# psoc6_01 register map
Vendor: Cypress Semiconductor; Series: PSoC6_01; File version: 1.0
CPU: CM4 r0p1, little endian, MPU, FPU, VTOR, 3 interrupt priority bits
Registers are 32-bit, read-write, reset 0x0 unless marked. A register's access mark holds for its fields unless they carry their own. Offsets are from the block's base; [hi:lo] are bit positions; lines under a group give offsets from that group.

## BLE (part 1 of 5) — Bluetooth Low Energy Subsystem
Base 0x403C0000
0x00 RCB group — Radio Control Bus (RCB) controller
  0x00 CTRL reset 0xF80000 — RCB control register.
    [31] ENABLED, [23] DATA_WIDTH, [22:19] ADDR_WIDTH, [18:13] DIV, [12] DIV_ENABLED, [11:10] LAG, [9:8] LEAD, [5] SSEL_POLARITY, [4] SCLK_CONTINUOUS, [3] RX_CLK_SRC, [2] RX_CLK_EDGE, [1] TX_CLK_EDGE
  0x04 STATUS ro reset not defined — RCB status register.
    [0] BUS_BUSY — RCB bus is busy. The bus is considered busy ('1') during an ongoing transaction.
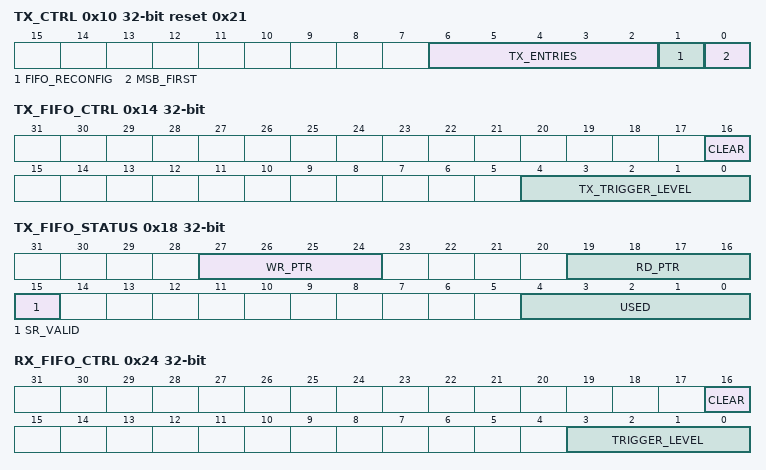
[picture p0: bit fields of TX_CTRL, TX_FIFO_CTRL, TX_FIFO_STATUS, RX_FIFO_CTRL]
  0x10 TX_CTRL reset 0x21 — Transmitter control register.
    [6:2] TX_ENTRIES — This field determines the depth of the TX_FIFO. Allowed legal values are 8 and 16 only
    [1] FIFO_RECONFIG — Setting this bit, clears the FIFO and resets the pointer
    [0] MSB_FIRST — Least significant bit first ('0') or most significant bit first ('1'). This field also affects the Address field When MSB_FIRST = 1, then [15:0] is data and [(ADDR_WIDTH+15):16] is used for address When MSB_FIRST = 0, then [15:0] is for data. No address field
  0x14 TX_FIFO_CTRL — Transmitter FIFO control register.
    [16] CLEAR — When '1', the transmitter FIFO and transmitter shift register are cleared/invalidated. Invalidation will last for as long as this field is '1'. If a quick clear/invalidation is required, the field should be set to '1' and be followed by a set to '0'. If a clear/invalidation is required for an extended time period, the field should be set to '1' during the complete time period.
    [4:0] TX_TRIGGER_LEVEL — Trigger level. When the transmitter FIFO has less entries than the number of this field, a transmitter trigger event is generated.
  0x18 TX_FIFO_STATUS ro — Transmitter FIFO status register.
    [27:24] WR_PTR — FIFO write pointer: FIFO location at which a new data frame is written.
    [19:16] RD_PTR — FIFO read pointer: FIFO location from which a data frame is read by the hardware.
    [15] SR_VALID — Indicates whether the TX shift registers holds a valid data frame ('1') or not ('0'). The shift register can be considered the top of the TX FIFO (the data frame is not included in the USED field of the TX FIFO). The shift register is a working register and holds the data frame that is currently transmitted (when the protocol state machine is transmitting a data frame) or the data frame that is tranmitted next (when the protocol state machine is not transmitting a data frame).
    [4:0] USED — Amount of enties in the transmitter FIFO. The value of this field ranges from 0 to 16
  0x1C TX_FIFO_WR wo — Transmitter FIFO write register.
    [31:0] DATA — Data frame written into the transmitter FIFO. Behavior is similar to that of a PUSH operation. A write to a full TX FIFO sets INTR_TX.OVERFLOW to '1'.
  0x20 RX_CTRL reset 0x1 — Receiver control register.
    [0] MSB_FIRST — Least significant bit first ('0') or most significant bit first ('1'). This field also affects the Address field When MSB_FIRST = 1, then [15:0] is data and [(ADDR_WIDTH+15):16] is used for address When MSB_FIRST = 0, then [15:0] is for data. No address field
  0x24 RX_FIFO_CTRL — Receiver FIFO control register.
    [16] CLEAR — When '1', the receiver FIFO and receiver shift register are cleared/invalidated. Invalidation will last for as long as this field is '1'. If a quick clear/invalidation is required, the field should be set to '1' and be followed by a set to '0'. If a clear/invalidation is required for an extended time period, the field should be set to '1' during the complete time period.
    [3:0] TRIGGER_LEVEL — Trigger level. When the receiver FIFO has more entries than the number of this field, a receiver trigger event is generated.
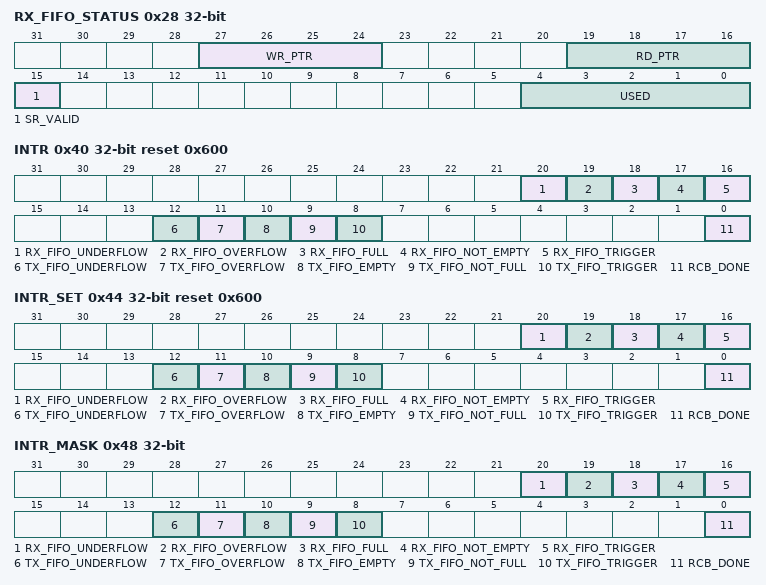
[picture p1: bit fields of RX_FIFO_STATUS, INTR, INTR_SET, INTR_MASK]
  0x28 RX_FIFO_STATUS ro — Receiver FIFO status register.
    [27:24] WR_PTR — FIFO write pointer: FIFO location at which a new data frame is written by the hardware.
    [19:16] RD_PTR — FIFO read pointer: FIFO location from which a data frame is read.
    [15] SR_VALID — Indicates whether the RX shift registers holds a (partial) valid data frame ('1') or not ('0'). The shift register can be considered the bottom of the RX FIFO (the data frame is not included in the USED field of the RX FIFO). The shift register is a working register and holds the data frame that is currently being received (when the protocol state machine is receiving a data frame).
    [4:0] USED — Amount of enties in the receiver FIFO. The value of this field ranges from 0 to FF_DATA_NR.
  0x2C RX_FIFO_RD ro reset not defined — Receiver FIFO read register.
    [31:0] DATA
  0x30 RX_FIFO_RD_SILENT ro reset not defined — Receiver FIFO read register.
    [31:0] DATA — Data read from the receiver FIFO. Reading a data frame will NOT remove the data frame from the FIFO; i.e. behavior is similar to that of a PEEK operation. A read from an empty RX FIFO sets INTR_RX.UNDERFLOW to '1'.
  0x40 INTR reset 0x600 — Master interrupt request register.
    [20] RX_FIFO_UNDERFLOW
    [19] RX_FIFO_OVERFLOW
    [18] RX_FIFO_FULL
    [17] RX_FIFO_NOT_EMPTY
    [16] RX_FIFO_TRIGGER
    [12] TX_FIFO_UNDERFLOW — Attempt to read from an empty TX FIFO. This happens when SCB is ready to transfer data and EMPTY is '1'. Only used in FIFO mode.
    [11] TX_FIFO_OVERFLOW
    [10] TX_FIFO_EMPTY
    [9] TX_FIFO_NOT_FULL
    [8] TX_FIFO_TRIGGER
    [0] RCB_DONE
  0x44 INTR_SET reset 0x600 — Master interrupt set request register
    [20] RX_FIFO_UNDERFLOW — Write with '1' to set corresponding bit in interrupt request register.
    [19] RX_FIFO_OVERFLOW — Write with '1' to set corresponding bit in interrupt request register.
    [18] RX_FIFO_FULL — Write with '1' to set corresponding bit in interrupt request register.
    [17] RX_FIFO_NOT_EMPTY — Write with '1' to set corresponding bit in interrupt request register.
    [16] RX_FIFO_TRIGGER — Write with '1' to set corresponding bit in interrupt request register.
    [12] TX_FIFO_UNDERFLOW — Write with '1' to set corresponding bit in interrupt request register.
    [11] TX_FIFO_OVERFLOW — Write with '1' to set corresponding bit in interrupt request register.
    [10] TX_FIFO_EMPTY — Write with '1' to set corresponding bit in interrupt request register.
    [9] TX_FIFO_NOT_FULL — Write with '1' to set corresponding bit in interrupt request register.
    [8] TX_FIFO_TRIGGER — Write with '1' to set corresponding bit in interrupt request register.
    [0] RCB_DONE — Write with '1' to set corresponding bit in interrupt request register.
  0x48 INTR_MASK — Master interrupt mask register.
    [20] RX_FIFO_UNDERFLOW — Mask bit for corresponding bit in interrupt request register.
    [19] RX_FIFO_OVERFLOW — Mask bit for corresponding bit in interrupt request register.
    [18] RX_FIFO_FULL — Mask bit for corresponding bit in interrupt request register.
    [17] RX_FIFO_NOT_EMPTY — Mask bit for corresponding bit in interrupt request register.
    [16] RX_FIFO_TRIGGER — Mask bit for corresponding bit in interrupt request register.
    [12] TX_FIFO_UNDERFLOW — Mask bit for corresponding bit in interrupt request register.
    [11] TX_FIFO_OVERFLOW — Mask bit for corresponding bit in interrupt request register.
    [10] TX_FIFO_EMPTY — Mask bit for corresponding bit in interrupt request register.
    [9] TX_FIFO_NOT_FULL — Mask bit for corresponding bit in interrupt request register.
    [8] TX_FIFO_TRIGGER — Mask bit for corresponding bit in interrupt request register.
    [0] RCB_DONE — Mask bit for corresponding bit in interrupt request register.
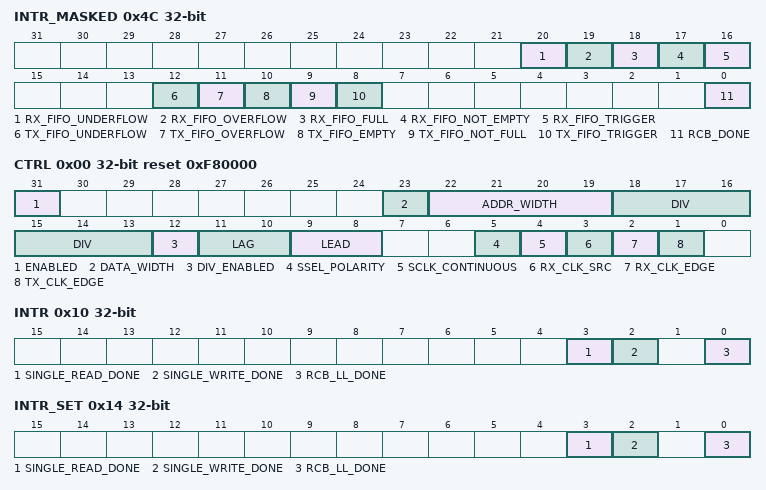
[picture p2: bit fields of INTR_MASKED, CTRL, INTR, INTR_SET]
  0x4C INTR_MASKED ro — Master interrupt masked request register
    [20] RX_FIFO_UNDERFLOW — Logical and of corresponding request and mask bits.
    [19] RX_FIFO_OVERFLOW — Logical and of corresponding request and mask bits.
    [18] RX_FIFO_FULL — Logical and of corresponding request and mask bits.
    [17] RX_FIFO_NOT_EMPTY — Logical and of corresponding request and mask bits.
    [16] RX_FIFO_TRIGGER — Logical and of corresponding request and mask bits.
    [12] TX_FIFO_UNDERFLOW — Logical and of corresponding request and mask bits.
    [11] TX_FIFO_OVERFLOW — Logical and of corresponding request and mask bits.
    [10] TX_FIFO_EMPTY — Logical and of corresponding request and mask bits.
    [9] TX_FIFO_NOT_FULL — Logical and of corresponding request and mask bits.
    [8] TX_FIFO_TRIGGER — Logical and of corresponding request and mask bits.
    [0] RCB_DONE — Logical and of corresponding request and mask bits.
  0x100 RCBLL group — Radio Control Bus (RCB) & Link Layer controller
    0x00 CTRL — RCB LL control register.
      [5] ENABLE_RADIO_BOD, [4] ALLOW_CPU_ACCESS_TX_RX, [3] CPU_SINGLE_READ, [2] CPU_SINGLE_WRITE, [1] RCBLL_CPU_REQ, [0] RCBLL_CTRL
    0x10 INTR — Master interrupt request register.
      [3] SINGLE_READ_DONE
      [2] SINGLE_WRITE_DONE
      [0] RCB_LL_DONE — RCB_LL is done and the access is given back to CPU
    0x14 INTR_SET — Master interrupt set request register
      [3] SINGLE_READ_DONE
      [2] SINGLE_WRITE_DONE
      [0] RCB_LL_DONE — Write with '1' to set corresponding bit in interrupt request register.
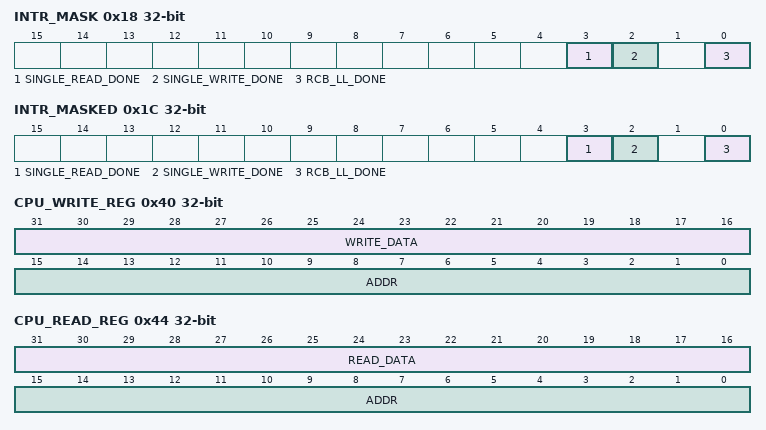
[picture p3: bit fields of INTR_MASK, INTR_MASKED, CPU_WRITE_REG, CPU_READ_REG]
    0x18 INTR_MASK — Master interrupt mask register.
      [3] SINGLE_READ_DONE
      [2] SINGLE_WRITE_DONE
      [0] RCB_LL_DONE — Mask bit for corresponding bit in interrupt request register.
    0x1C INTR_MASKED ro — Master interrupt masked request register
      [3] SINGLE_READ_DONE
      [2] SINGLE_WRITE_DONE
      [0] RCB_LL_DONE — Logical and of corresponding request and mask bits.
    0x20 RADIO_REG1_ADDR reset 0x1E02 — Address of Register#1 in Radio (MDON)
      [15:0] REG_ADDR
    0x24 RADIO_REG2_ADDR reset 0xA03 — Address of Register#2 in Radio (RSSI)
      [15:0] REG_ADDR
    0x28 RADIO_REG3_ADDR reset 0x824 — Address of Register#3 in Radio (ACCL)
      [15:0] REG_ADDR
    0x2C RADIO_REG4_ADDR reset 0x823 — Address of Register#4 in Radio (ACCH)
      [15:0] REG_ADDR
    0x30 RADIO_REG5_ADDR reset 0xA03 — Address of Register#5 in Radio (RSSI ENERGY)
      [15:0] REG_ADDR
    0x40 CPU_WRITE_REG
      [31:16] WRITE_DATA, [15:0] ADDR
    0x44 CPU_READ_REG
      [31:16] READ_DATA ro, [15:0] ADDR
